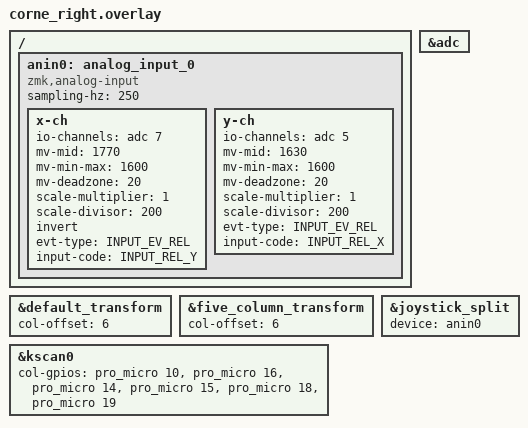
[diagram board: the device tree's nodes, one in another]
/*
 * Copyright (c) 2020 Pete Johanson
 *
 * SPDX-License-Identifier: MIT
 */

#include "corne.dtsi"
#include <zephyr/dt-bindings/input/input-event-codes.h>

&default_transform {
    col-offset = <6>;
};

&five_column_transform {
    col-offset = <6>;
};

&kscan0 {
    col-gpios
        = <&pro_micro 10 GPIO_ACTIVE_HIGH>
        , <&pro_micro 16 GPIO_ACTIVE_HIGH>
        , <&pro_micro 14 GPIO_ACTIVE_HIGH>
        , <&pro_micro 15 GPIO_ACTIVE_HIGH>
        , <&pro_micro 18 GPIO_ACTIVE_HIGH>
        , <&pro_micro 19 GPIO_ACTIVE_HIGH>
        ;
};

#include <zephyr/dt-bindings/input/input-event-codes.h>
/* Reference: https://docs.zephyrproject.org/apidoc/latest/group__input__events.html */

&adc {
	status = "okay";
};

/ {
	anin0: analog_input_0 {
		compatible = "zmk,analog-input";
		sampling-hz = <250>;
		x-ch {
			io-channels = <&adc 7>; // <--- see ain-map.png for nRF52840
			mv-mid = <1770>;
			mv-min-max = <1600>;
			mv-deadzone = <20>;
			scale-multiplier = <1>;
			scale-divisor = <200>;
			invert;
			evt-type = <INPUT_EV_REL>;
			input-code = <INPUT_REL_Y>;
		};
		y-ch {
			io-channels = <&adc 5>; // <--- see ain-map.png for nRF52840
			mv-mid = <1630>;
			mv-min-max = <1600>;
			mv-deadzone = <20>;
			scale-multiplier = <1>;
			scale-divisor = <200>;
			// invert;
			evt-type = <INPUT_EV_REL>;
			input-code = <INPUT_REL_X>;

			/* enable report mdoe for gamepad axix or knob */
			/* to only call input_report on quantquantized value is updated */
			/* NOTE: mouse input does NOT need this */
			// report-on-change-only;

		};
	};
};
&joystick_split {
			device = <&anin0>;
};
